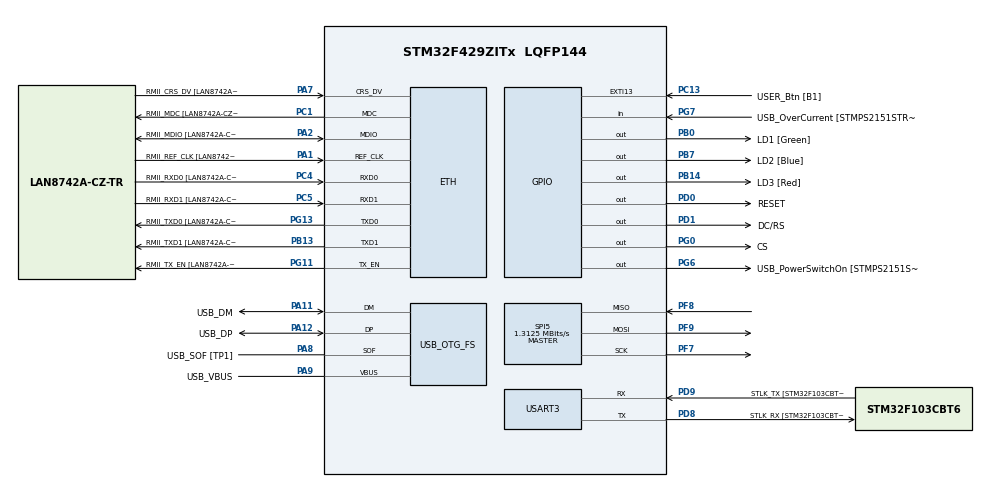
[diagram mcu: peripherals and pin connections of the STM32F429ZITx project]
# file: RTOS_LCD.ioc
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ETH.MediaInterface=HAL_ETH_RMII_MODE
ETH.PHY_Name=LAN8742A_PHY_ADDRESS
ETH.PHY_Value=0
ETH.PhyAddress=0
FREERTOS.Tasks01=LCDTask,24,2048,LCD_Task,Default,NULL,Dynamic,NULL,NULL
Mcu.Family=STM32F4
Mcu.Name=STM32F429ZITx
Mcu.Package=LQFP144
NVIC.EXTI15_10_IRQn=true\:5\:0\:false\:false\:true\:true\:true\:true\:true
NVIC.PriorityGroup=NVIC_PRIORITYGROUP_4
PA1.GPIO_Label=RMII_REF_CLK [LAN8742A-CZ-TR_REFCLK0]
PA1.Mode=RMII
PA1.Signal=ETH_REF_CLK
PA10.GPIO_Label=USB_ID
PA10.Signal=USB_OTG_FS_ID
PA11.GPIO_Label=USB_DM
PA11.Mode=Device_Only
PA11.Signal=USB_OTG_FS_DM
PA12.GPIO_Label=USB_DP
PA12.Mode=Device_Only
PA12.Signal=USB_OTG_FS_DP
PA13.GPIO_Label=TMS
PA13.Mode=Serial_Wire
PA13.Signal=SYS_JTMS-SWDIO
PA14.GPIO_Label=TCK
PA14.Mode=Serial_Wire
PA14.Signal=SYS_JTCK-SWCLK
PA2.GPIO_Label=RMII_MDIO [LAN8742A-CZ-TR_MDIO]
PA2.Mode=RMII
PA2.Signal=ETH_MDIO
PA7.GPIO_Label=RMII_CRS_DV [LAN8742A-CZ-TR_CRS_DV]
PA7.Mode=RMII
PA7.Signal=ETH_CRS_DV
PA8.GPIO_Label=USB_SOF [TP1]
PA8.Mode=Activate_SOF_FS
PA8.Signal=USB_OTG_FS_SOF
PA9.GPIO_Label=USB_VBUS
PA9.Mode=Activate_VBUS
PA9.Signal=USB_OTG_FS_VBUS
PB0.GPIO_Label=LD1 [Green]
PB0.Signal=GPIO_Output
PB13.GPIO_Label=RMII_TXD1 [LAN8742A-CZ-TR_TXD1]
PB13.Mode=RMII
PB13.Signal=ETH_TXD1
PB14.GPIO_Label=LD3 [Red]
PB14.Signal=GPIO_Output
PB7.GPIO_Label=LD2 [Blue]
PB7.Signal=GPIO_Output
PC1.GPIO_Label=RMII_MDC [LAN8742A-CZ-TR_MDC]
PC1.Mode=RMII
PC1.Signal=ETH_MDC
PC13.GPIO_Label=USER_Btn [B1]
PC13.Signal=GPXTI13
PC14/OSC32_IN.Mode=LSE-External-Oscillator
PC14/OSC32_IN.Signal=RCC_OSC32_IN
PC15/OSC32_OUT.Mode=LSE-External-Oscillator
PC15/OSC32_OUT.Signal=RCC_OSC32_OUT
PC4.GPIO_Label=RMII_RXD0 [LAN8742A-CZ-TR_RXD0]
PC4.Mode=RMII
PC4.Signal=ETH_RXD0
PC5.GPIO_Label=RMII_RXD1 [LAN8742A-CZ-TR_RXD1]
PC5.Mode=RMII
PC5.Signal=ETH_RXD1
PD0.GPIO_Label=RESET
PD0.Signal=GPIO_Output
PD1.GPIO_Label=DC/RS
PD1.Signal=GPIO_Output
PD8.GPIO_Label=STLK_RX [STM32F103CBT6_PA3]
PD8.Mode=Asynchronous
PD8.Signal=USART3_TX
PD9.GPIO_Label=STLK_TX [STM32F103CBT6_PA2]
PD9.Mode=Asynchronous
PD9.Signal=USART3_RX
PF7.Mode=Full_Duplex_Master
PF7.Signal=SPI5_SCK
PF8.Mode=Full_Duplex_Master
PF8.Signal=SPI5_MISO
PF9.Mode=Full_Duplex_Master
PF9.Signal=SPI5_MOSI
PG0.GPIO_Label=CS
PG0.Signal=GPIO_Output
PG11.GPIO_Label=RMII_TX_EN [LAN8742A-CZ-TR_TXEN]
PG11.Mode=RMII
PG11.Signal=ETH_TX_EN
PG13.GPIO_Label=RMII_TXD0 [LAN8742A-CZ-TR_TXD0]
PG13.Mode=RMII
PG13.Signal=ETH_TXD0
PG6.GPIO_Label=USB_PowerSwitchOn [STMPS2151STR_EN]
PG6.Signal=GPIO_Output
PG7.GPIO_Label=USB_OverCurrent [STMPS2151STR_FAULT]
PG7.Signal=GPIO_Input
PH0/OSC_IN.GPIO_Label=MCO [STM32F103CBT6_PA8]
PH0/OSC_IN.Mode=HSE-External-Clock-Source
PH0/OSC_IN.Signal=RCC_OSC_IN
PH1/OSC_OUT.Mode=HSE-External-Clock-Source
PH1/OSC_OUT.Signal=RCC_OSC_OUT
ProjectManager.HeapSize=0x200
ProjectManager.StackSize=0x400
ProjectManager.TargetToolchain=STM32CubeIDE
RCC.48MHZClocksFreq_Value=48000000
RCC.AHBFreq_Value=168000000
RCC.APB1CLKDivider=RCC_HCLK_DIV4
RCC.APB1Freq_Value=42000000
RCC.APB1TimFreq_Value=84000000
RCC.APB2CLKDivider=RCC_HCLK_DIV2
RCC.APB2Freq_Value=84000000
RCC.APB2TimCLKDivider=2
RCC.APB2TimFreq_Value=168000000
RCC.CortexFreq_Value=168000000
RCC.HCLKFreq_Value=168000000
RCC.HSE_VALUE=8000000
RCC.HSI_VALUE=16000000
RCC.PLLM=4
RCC.PLLMUL=RCC_PLL_MUL9
RCC.PLLN=168
RCC.PLLQ=7
RCC.PRESCALERUSB=RCC_USBCLKSOURCE_PLL_DIV1_5
RCC.SYSCLKFreq_VALUE=168000000
RCC.SYSCLKSource=RCC_SYSCLKSOURCE_PLLCLK
RCC.SYSCLKSourceVirtual=RCC_SYSCLKSOURCE_PLLCLK
RCC.USBFreq_Value=48000000
RCC.VCOOutputFreq_Value=336000000
SPI5.BaudRatePrescaler=SPI_BAUDRATEPRESCALER_64
SPI5.CalculateBaudRate=1.3125 MBits/s
SPI5.Direction=SPI_DIRECTION_2LINES
SPI5.Mode=SPI_MODE_MASTER
SPI5.VirtualType=VM_MASTER
USART3.VirtualMode=VM_ASYNC
USB_OTG_FS.VirtualMode=Device_Only
VP_FREERTOS_VS_CMSIS_V2.Mode=CMSIS_V2
board=NUCLEO-F429ZI

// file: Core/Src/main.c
	/* USER CODE BEGIN Header */
	/**
	  ******************************************************************************
	  * @file           : main.c
	  * @brief          : Main program body
	  ******************************************************************************
	  * @attention
	  *
	  * Copyright (c) 2026 STMicroelectronics.
	  * All rights reserved.
	  *
	  * This software is licensed under terms that can be found in the LICENSE file
	  * in the root directory of this software component.
	  * If no LICENSE file comes with this software, it is provided AS-IS.
	  *
	  ******************************************************************************
	  */
	/* USER CODE END Header */
	/* Includes ------------------------------------------------------------------*/
	#include "main.h"
	#include "string.h"
	#include "cmsis_os.h"

	/* Private includes ----------------------------------------------------------*/
	/* USER CODE BEGIN Includes */
	#include "FreeRTOS.h"
	#include "task.h"
	#include "queue.h"
	#include "ui.h"
	/* USER CODE END Includes */

	/* Private typedef -----------------------------------------------------------*/

	/* Private define ------------------------------------------------------------*/

	/* Private macro -------------------------------------------------------------*/

	/* Private variables ---------------------------------------------------------*/

	ETH_TxPacketConfig TxConfig;
	ETH_DMADescTypeDef  DMARxDscrTab[ETH_RX_DESC_CNT]; /* Ethernet Rx DMA Descriptors */
	ETH_DMADescTypeDef  DMATxDscrTab[ETH_TX_DESC_CNT]; /* Ethernet Tx DMA Descriptors */

	ETH_HandleTypeDef heth;

	SPI_HandleTypeDef hspi5;

	UART_HandleTypeDef huart3;

	PCD_HandleTypeDef hpcd_USB_OTG_FS;

	/* Definitions for LCDTask */
	osThreadId_t LCDTaskHandle;
	const osThreadAttr_t LCDTask_attributes = {
	  .name = "LCDTask",
	  .stack_size = 2048 * 4,
	  .priority = (osPriority_t) osPriorityNormal,
	};

	/* Private function prototypes -----------------------------------------------*/
	void SystemClock_Config(void);
	static void MX_GPIO_Init(void);
	static void MX_ETH_Init(void);
	static void MX_USART3_UART_Init(void);
	static void MX_USB_OTG_FS_PCD_Init(void);
	static void MX_SPI5_Init(void);
	void LCD_Task(void *argument);

	/* Private user code ---------------------------------------------------------*/

	/**
	  * @brief  The application entry point.
	  * @retval int
	  */
	int main(void)
	{

	  /* MCU Configuration--------------------------------------------------------*/

	  /* Reset of all peripherals, Initializes the Flash interface and the Systick. */
	  HAL_Init();

	  /* Configure the system clock */
	  SystemClock_Config();

	  /* Initialize all configured peripherals */
	  MX_GPIO_Init();
	  MX_ETH_Init();
	  MX_USART3_UART_Init();
	  MX_USB_OTG_FS_PCD_Init();
	  MX_SPI5_Init();

	  /* Init scheduler */
	  osKernelInitialize();

	  /* Create the thread(s) */
	  /* creation of LCDTask */
	  //LCDTaskHandle = osThreadNew(LCD_Task, NULL, &LCDTask_attributes);

	  /* USER CODE BEGIN RTOS_THREADS */
	  /* add threads, ... */
	  UI_Init();
	  /* USER CODE END RTOS_THREADS */

	  /* Start scheduler */
	  vTaskStartScheduler();

	  /* We should never get here as control is now taken by the scheduler */

	  /* Infinite loop */
	  while (1)
	  {

	  }
	}

	/**
	  * @brief System Clock Configuration
	  * @retval None
	  */
	void SystemClock_Config(void)
	{
	  RCC_OscInitTypeDef RCC_OscInitStruct = {0};
	  RCC_ClkInitTypeDef RCC_ClkInitStruct = {0};

	  /** Configure the main internal regulator output voltage
	  */
	  __HAL_RCC_PWR_CLK_ENABLE();
	  __HAL_PWR_VOLTAGESCALING_CONFIG(PWR_REGULATOR_VOLTAGE_SCALE1);

	  /** Initializes the RCC Oscillators according to the specified parameters
	  * in the RCC_OscInitTypeDef structure.
	  */
	  RCC_OscInitStruct.OscillatorType = RCC_OSCILLATORTYPE_HSE;
	  RCC_OscInitStruct.HSEState = RCC_HSE_BYPASS;
	  RCC_OscInitStruct.PLL.PLLState = RCC_PLL_ON;
	  RCC_OscInitStruct.PLL.PLLSource = RCC_PLLSOURCE_HSE;
	  RCC_OscInitStruct.PLL.PLLM = 4;
	  RCC_OscInitStruct.PLL.PLLN = 168;
	  RCC_OscInitStruct.PLL.PLLP = RCC_PLLP_DIV2;
	  RCC_OscInitStruct.PLL.PLLQ = 7;
	  if (HAL_RCC_OscConfig(&RCC_OscInitStruct) != HAL_OK)
	  {
		Error_Handler();
	  }

	  /** Initializes the CPU, AHB and APB buses clocks
	  */
	  RCC_ClkInitStruct.ClockType = RCC_CLOCKTYPE_HCLK|RCC_CLOCKTYPE_SYSCLK
								  |RCC_CLOCKTYPE_PCLK1|RCC_CLOCKTYPE_PCLK2;
	  RCC_ClkInitStruct.SYSCLKSource = RCC_SYSCLKSOURCE_PLLCLK;
	  RCC_ClkInitStruct.AHBCLKDivider = RCC_SYSCLK_DIV1;
	  RCC_ClkInitStruct.APB1CLKDivider = RCC_HCLK_DIV4;
	  RCC_ClkInitStruct.APB2CLKDivider = RCC_HCLK_DIV2;

	  if (HAL_RCC_ClockConfig(&RCC_ClkInitStruct, FLASH_LATENCY_5) != HAL_OK)
	  {
		Error_Handler();
	  }
	}

	/**
	  * @brief ETH Initialization Function
	  * @param None
	  * @retval None
	  */
	static void MX_ETH_Init(void)
	{

	   static uint8_t MACAddr[6];

	  heth.Instance = ETH;
	  MACAddr[0] = 0x00;
	  MACAddr[1] = 0x80;
	  MACAddr[2] = 0xE1;
	  MACAddr[3] = 0x00;
	  MACAddr[4] = 0x00;
	  MACAddr[5] = 0x00;
	  heth.Init.MACAddr = &MACAddr[0];
	  heth.Init.MediaInterface = HAL_ETH_RMII_MODE;
	  heth.Init.TxDesc = DMATxDscrTab;
	  heth.Init.RxDesc = DMARxDscrTab;
	  heth.Init.RxBuffLen = 1524;

	  if (HAL_ETH_Init(&heth) != HAL_OK)
	  {
		Error_Handler();
	  }

	  memset(&TxConfig, 0 , sizeof(ETH_TxPacketConfig));
	  TxConfig.Attributes = ETH_TX_PACKETS_FEATURES_CSUM | ETH_TX_PACKETS_FEATURES_CRCPAD;
	  TxConfig.ChecksumCtrl = ETH_CHECKSUM_IPHDR_PAYLOAD_INSERT_PHDR_CALC;
	  TxConfig.CRCPadCtrl = ETH_CRC_PAD_INSERT;

	}

	/**
	  * @brief SPI5 Initialization Function
	  * @param None
	  * @retval None
	  */
	static void MX_SPI5_Init(void)
	{

	  /* SPI5 parameter configuration*/
	  hspi5.Instance = SPI5;
	  hspi5.Init.Mode = SPI_MODE_MASTER;
	  hspi5.Init.Direction = SPI_DIRECTION_2LINES;
	  hspi5.Init.DataSize = SPI_DATASIZE_8BIT;
	  hspi5.Init.CLKPolarity = SPI_POLARITY_LOW;
	  hspi5.Init.CLKPhase = SPI_PHASE_1EDGE;
	  hspi5.Init.NSS = SPI_NSS_SOFT;
	  hspi5.Init.BaudRatePrescaler = SPI_BAUDRATEPRESCALER_64;
	  hspi5.Init.FirstBit = SPI_FIRSTBIT_MSB;
	  hspi5.Init.TIMode = SPI_TIMODE_DISABLE;
	  hspi5.Init.CRCCalculation = SPI_CRCCALCULATION_DISABLE;
	  hspi5.Init.CRCPolynomial = 10;
	  if (HAL_SPI_Init(&hspi5) != HAL_OK)
	  {
		Error_Handler();
	  }

	}

	/**
	  * @brief USART3 Initialization Function
	  * @param None
	  * @retval None
	  */
	static void MX_USART3_UART_Init(void)
	{

	  huart3.Instance = USART3;
	  huart3.Init.BaudRate = 115200;
	  huart3.Init.WordLength = UART_WORDLENGTH_8B;
	  huart3.Init.StopBits = UART_STOPBITS_1;
	  huart3.Init.Parity = UART_PARITY_NONE;
	  huart3.Init.Mode = UART_MODE_TX_RX;
	  huart3.Init.HwFlowCtl = UART_HWCONTROL_NONE;
	  huart3.Init.OverSampling = UART_OVERSAMPLING_16;
	  if (HAL_UART_Init(&huart3) != HAL_OK)
	  {
		Error_Handler();
	  }

	}

	/**
	  * @brief USB_OTG_FS Initialization Function
	  * @param None
	  * @retval None
	  */
	static void MX_USB_OTG_FS_PCD_Init(void)
	{

	  hpcd_USB_OTG_FS.Instance = USB_OTG_FS;
	  hpcd_USB_OTG_FS.Init.dev_endpoints = 4;
	  hpcd_USB_OTG_FS.Init.speed = PCD_SPEED_FULL;
	  hpcd_USB_OTG_FS.Init.dma_enable = DISABLE;
	  hpcd_USB_OTG_FS.Init.phy_itface = PCD_PHY_EMBEDDED;
	  hpcd_USB_OTG_FS.Init.Sof_enable = ENABLE;
	  hpcd_USB_OTG_FS.Init.low_power_enable = DISABLE;
	  hpcd_USB_OTG_FS.Init.lpm_enable = DISABLE;
	  hpcd_USB_OTG_FS.Init.vbus_sensing_enable = ENABLE;
	  hpcd_USB_OTG_FS.Init.use_dedicated_ep1 = DISABLE;
	  if (HAL_PCD_Init(&hpcd_USB_OTG_FS) != HAL_OK)
	  {
		Error_Handler();
	  }

	}

	/**
	  * @brief GPIO Initialization Function
	  * @param None
	  * @retval None
	  */
	static void MX_GPIO_Init(void)
	{
	  GPIO_InitTypeDef GPIO_InitStruct = {0};

	  /* GPIO Ports Clock Enable */
	  __HAL_RCC_GPIOC_CLK_ENABLE();
	  __HAL_RCC_GPIOF_CLK_ENABLE();
	  __HAL_RCC_GPIOH_CLK_ENABLE();
	  __HAL_RCC_GPIOA_CLK_ENABLE();
	  __HAL_RCC_GPIOB_CLK_ENABLE();
	  __HAL_RCC_GPIOG_CLK_ENABLE();
	  __HAL_RCC_GPIOD_CLK_ENABLE();

	  /*Configure GPIO pin Output Level */
	  HAL_GPIO_WritePin(GPIOB, LD1_Pin|LD3_Pin|LD2_Pin, GPIO_PIN_RESET);

	  /*Configure GPIO pin Output Level */
	  HAL_GPIO_WritePin(GPIOG, CS_Pin|USB_PowerSwitchOn_Pin, GPIO_PIN_RESET);

	  /*Configure GPIO pin Output Level */
	  HAL_GPIO_WritePin(GPIOD, RESET_Pin|DC_RS_Pin, GPIO_PIN_RESET);

	  /*Configure GPIO pin : USER_Btn_Pin */
	  GPIO_InitStruct.Pin = USER_Btn_Pin;
	  GPIO_InitStruct.Mode = GPIO_MODE_IT_RISING;
	  GPIO_InitStruct.Pull = GPIO_NOPULL;
	  HAL_GPIO_Init(USER_Btn_GPIO_Port, &GPIO_InitStruct);

	  /*Configure GPIO pins : LD1_Pin LD3_Pin LD2_Pin */
	  GPIO_InitStruct.Pin = LD1_Pin|LD3_Pin|LD2_Pin;
	  GPIO_InitStruct.Mode = GPIO_MODE_OUTPUT_PP;
	  GPIO_InitStruct.Pull = GPIO_NOPULL;
	  GPIO_InitStruct.Speed = GPIO_SPEED_FREQ_LOW;
	  HAL_GPIO_Init(GPIOB, &GPIO_InitStruct);

	  /*Configure GPIO pins : CS_Pin USB_PowerSwitchOn_Pin */
	  GPIO_InitStruct.Pin = CS_Pin|USB_PowerSwitchOn_Pin;
	  GPIO_InitStruct.Mode = GPIO_MODE_OUTPUT_PP;
	  GPIO_InitStruct.Pull = GPIO_NOPULL;
	  GPIO_InitStruct.Speed = GPIO_SPEED_FREQ_LOW;
	  HAL_GPIO_Init(GPIOG, &GPIO_InitStruct);

	  /*Configure GPIO pin : USB_OverCurrent_Pin */
	  GPIO_InitStruct.Pin = USB_OverCurrent_Pin;
	  GPIO_InitStruct.Mode = GPIO_MODE_INPUT;
	  GPIO_InitStruct.Pull = GPIO_NOPULL;
	  HAL_GPIO_Init(USB_OverCurrent_GPIO_Port, &GPIO_InitStruct);

	  /*Configure GPIO pins : RESET_Pin DC_RS_Pin */
	  GPIO_InitStruct.Pin = RESET_Pin|DC_RS_Pin;
	  GPIO_InitStruct.Mode = GPIO_MODE_OUTPUT_PP;
	  GPIO_InitStruct.Pull = GPIO_NOPULL;
	  GPIO_InitStruct.Speed = GPIO_SPEED_FREQ_LOW;
	  HAL_GPIO_Init(GPIOD, &GPIO_InitStruct);

	  /* EXTI interrupt init*/
	  HAL_NVIC_SetPriority(EXTI15_10_IRQn, 5, 0);
	  HAL_NVIC_EnableIRQ(EXTI15_10_IRQn);

	}

	void LCD_Task(void *argument)
	{
	  /* USER CODE BEGIN 5 */
	  /* Infinite loop */
	  for(;;)
	  {
		vTaskDelay(pdMS_TO_TICKS(1000));
	  }
	  /* USER CODE END 5 */
	}

	/**
	  * @brief  This function is executed in case of error occurrence.
	  * @retval None
	  */
	void Error_Handler(void)
	{
	  __disable_irq();
	  while (1)
	  {
	  }
	}
	#ifdef USE_FULL_ASSERT
	/**
	  * @brief  Reports the name of the source file and the source line number
	  *         where the assert_param error has occurred.
	  * @param  file: pointer to the source file name
	  * @param  line: assert_param error line source number
	  * @retval None
	  */
	void assert_failed(uint8_t *file, uint32_t line)
	{
	}
	#endif /* USE_FULL_ASSERT */
